# LPC11Axx register map
File version: 0.6
CPU: CM0 r0p0, little endian, no MPU, no FPU, 2 interrupt priority bits
Registers are 32-bit, read-write, reset 0x0 unless marked. A register's access mark holds for its fields unless they carry their own. Offsets are from the block's base; [hi:lo] are bit positions; {n}, {i} and the like mark numbered series.

## CMP — Comparator
Base 0x40028000
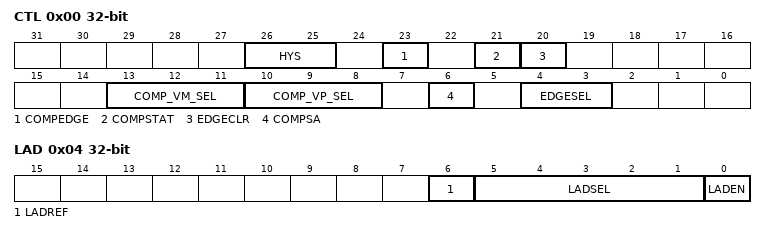
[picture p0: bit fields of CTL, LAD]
0x00 CTL — Comparator control register
  [26:25] HYS — Controls the hysteresis of the comparator. When the comparator is outputting a certain state, this is the difference between the selected signals, in the opposite direction from the state being output, that will switch the output.
    0=NOHYSTERESIS (None (the output will switch as the voltages cross)); 1=HYS5MV (5 mV); 2=HSY10MV (10 mV); 3=HSY20MV (20 mV)
  [23] COMPEDGE — Comparator edge-detect status.
  [21] COMPSTAT — Comparator status. This bit reflects the state of the comparator output.
  [20] EDGECLR — Interrupt clear bit. Writing a 1 to this bit clears the COMPEDGE bit (bit 23 below) and thus negates the interrupt request.
  [13:11] COMP_VM_SEL — Selects negative voltage input
    0=VLADDOUT (voltage ladder output); {v}=ACMPI{v} (v=1..5); 6=INTVOLTAGEREF (internal reference voltage)
  [10:8] COMP_VP_SEL — Selects positive voltage input
    0=VLADOUT (voltage ladder output); {v}=ACMPI{v} (v=1..5); 6=INTVOLTAGEREF (internal reference voltage); 7=TEMPSENSOR (temperature sensor)
  [6] COMPSA — Comarator output control
    0=DIRECT (Uses the comparator output directly.); 1=SYNCH (Synchronizes the comparator output to the bus clock for output to other modules.)
  [4:3] EDGESEL — This field controls which edges on the comparator output set the COMPEDGE bit (bit 23 below): 00 = Falling edges 01 = Rising edges 1x = Both edges
    0=FALLING (Falling edges); 1=RISING (Rising edges); 2=DUALEDGE (Both edges); 3=DUALEDGE (Both edges)
0x04 LAD — Voltage ladder register
  [6] LADREF — Selects the reference voltage for the voltage ladder
    0=VDDPIN; 1=VDDCMPPIN
  [5:1] LADSEL — Voltage ladder value. The reference voltage Vref depends on the LADREF bit below. 00000 = VSS 00001 = 1 Vref/31 00010 = 2 Vref/31 ... 11111 = Vref
  [0] LADEN — Voltage ladder enable

## GPIO_PIN_INT — GPIO Modification
Base 0x4004C000
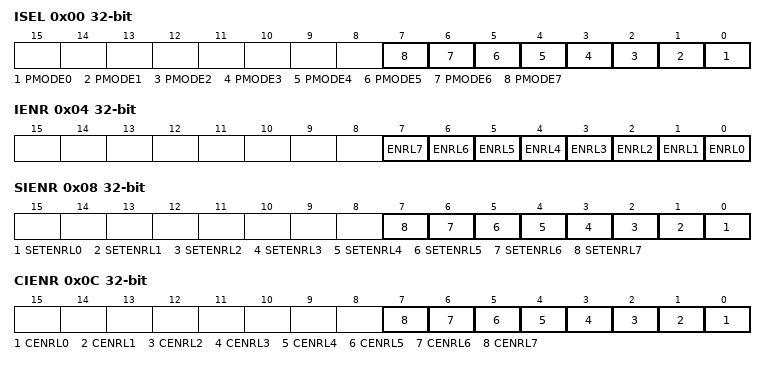
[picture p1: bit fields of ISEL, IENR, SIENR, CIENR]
0x00 ISEL — Pin Interrupt Mode register
  [n] PMODE{n} (n=0..7) — Selects the interrupt mode for each pin interrupt. Bit n configures the pin interrupt selected in PINTSELn. 0 = Edge sensitive 1 = Level sensitive
0x04 IENR — Pin Interrupt Enable (Rising) register
  [n] ENRL{n} (n=0..7) — Enables the rising edge or level interrupt for each pin interrupt. Bit n configures the pin interrupt selected in PINTSELn. 0 = Disable rising edge or level interrupt. 1 = Enable rising edge or level interrupt.
0x08 SIENR wo reset not defined — Set Pin Interrupt Enable (Rising) register
  [n] SETENRL{n} (n=0..7) — Ones written to this address set bits in the PINTEN_R, thus enabling interrupts. Bit n sets bit n in the PINTEN_R register. 0 = No operation. 1 = Enable rising edge or level interrupt.
0x0C CIENR wo reset not defined — Clear Pin Interrupt Enable (Rising) register
  [n] CENRL{n} (n=0..7) — Ones written to this address clear bits in the IENR, thus disabling the interrupts. Bit n clears bit n in the IENR register. 0 = No operation. 1 = Disable rising edge or level interrupt.
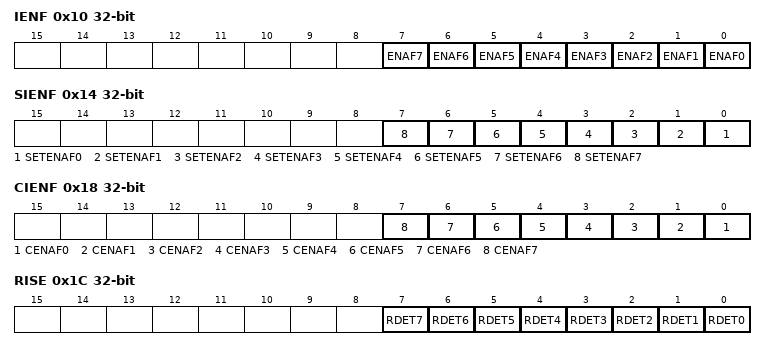
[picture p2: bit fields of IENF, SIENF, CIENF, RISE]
0x10 IENF — Pin Interrupt Enable Falling Edge / Active Level register
  [n] ENAF{n} (n=0..7) — Enables the falling edge or configures the active level interrupt for each pin interrupt. Bit n configures the pin interrupt selected in PINTSELn. 0 = Disable falling edge interrupt or set active interrupt level LOW. 1 = Enable falling edge interrupt enabled or set active interrupt level HIGH.
0x14 SIENF wo reset not defined — Set Pin Interrupt Enable Falling Edge / Active Level register
  [n] SETENAF{n} (n=0..7) — Ones written to this address set bits in the IENF, thus enabling interrupts. Bit n sets bit n in the IENF register. 0 = No operation. 1 = Select HIGH-active interrupt or enable falling edge interrupt.
0x18 CIENF wo reset not defined — Clear Pin Interrupt Enable Falling Edge / Active Level address
  [n] CENAF{n} (n=0..7) — Ones written to this address clears bits in the IENF, thus disabling interrupts. Bit n clears bit n in the IENF register. 0 = No operation. 1 = LOW-active interrupt selected or falling edge interrupt disabled.
0x1C RISE — Pin Interrupt Rising Edge register
  [n] RDET{n} (n=0..7) — Rising edge detect. Bit n detects the rising edge of the pin selected in PINTSELn. Read 0: No rising edge has been detected on this pin since Reset or the last time a one was written to this bit. Write 0: no operation. Read 1: a rising edge has been detected since Reset or the last time a one was written to this bit. Write 1: clear rising edge detection for this pin.
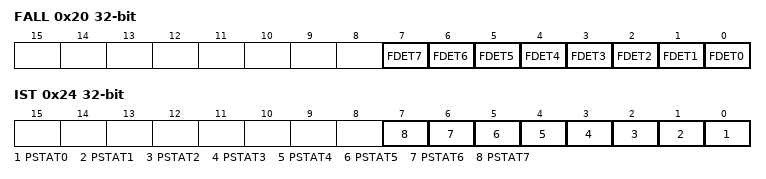
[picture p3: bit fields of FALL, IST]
0x20 FALL — Pin Interrupt Falling Edge register
  [n] FDET{n} (n=0..7) — Falling edge detect. Bit n detects the falling edge of the pin selected in PINTSELn. Read 0: No falling edge has been detected on this pin since Reset or the last time a one was written to this bit. Write 0: no operation. Read 1: a falling edge has been detected since Reset or the last time a one was written to this bit. Write 1: clear falling edge detection for this pin.
0x24 IST — Pin Interrupt Status register
  [n] PSTAT{n} (n=0..7) — Pin interrupt status. Bit n returns the status, clears the edge interrupt, or inverts the active level of the pin selected in PINTSELn. Read 0: interrupt is not being requested for this interrupt pin. Write 0: no operation. Read 1: interrupt is being requested for this interrupt pin. Write 1 (edge-sensitive): clear rising- and falling-edge detection for this pin. Write 1 (level-sensitive): switch the active level for this pin (in the PINTENT_F register).
